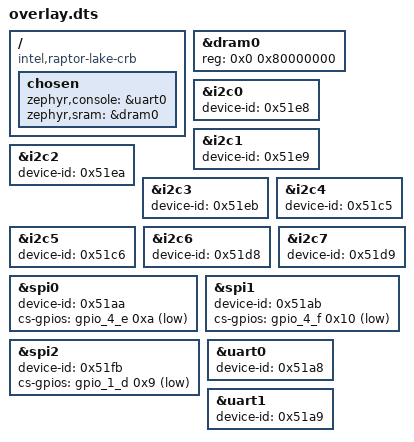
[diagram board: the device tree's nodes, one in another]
/ {
	compatible = "intel,raptor-lake-crb";
	chosen {
		zephyr,console = &uart0;
		zephyr,sram = &dram0;
	};
};
&dram0{
	reg = < 0x0 0x80000000 >;
};
&i2c0{
	device-id = < 0x51e8 >;
};
&i2c1{
	device-id = < 0x51e9 >;
	status = "okay";
};
&i2c2{
	device-id = < 0x51ea >;
};
&i2c3{
	device-id = < 0x51eb >;
};
&i2c4{
	device-id = < 0x51c5 >;
};
&i2c5{
	device-id = < 0x51c6 >;
};
&i2c6{
	device-id = < 0x51d8 >;
};
&i2c7{
	device-id = < 0x51d9 >;
};
&spi0{
	device-id = < 0x51aa >;
	cs-gpios = < &gpio_4_e 0xa 0x1 >;
};
&spi1{
	device-id = < 0x51ab >;
	cs-gpios = < &gpio_4_f 0x10 0x1 >;
};
&spi2{
	device-id = < 0x51fb >;
	cs-gpios = < &gpio_1_d 0x9 0x1 >;
};
&uart0{
	device-id = < 0x51a8 >;
	status = "okay";
};
&uart1{
	device-id = < 0x51a9 >;
	status = "okay";
};
